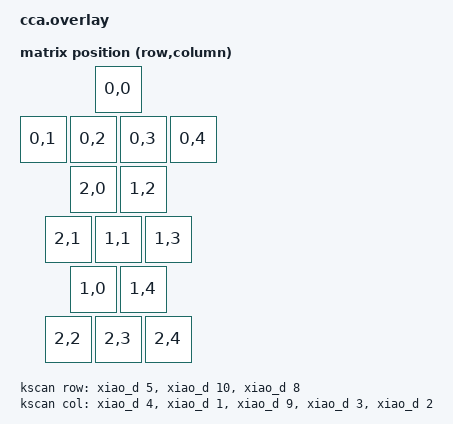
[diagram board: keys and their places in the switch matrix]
// This file was generated from a template. Edit it to match your keyboard.
// See https://zmk.dev/docs/development/hardware-integration/new-shield for more
// instructions.

#include <dt-bindings/zmk/matrix_transform.h>

#include "cca-layouts.dtsi"

/ {
    chosen {
        zmk,physical-layout = &default_layout;
    };

    kscan: kscan {
        compatible = "zmk,kscan-gpio-matrix";
        diode-direction = "col2row";
        wakeup-source;

        col-gpios
            = <&xiao_d 4 GPIO_ACTIVE_HIGH>
            , <&xiao_d 1 GPIO_ACTIVE_HIGH>
            , <&xiao_d 9 GPIO_ACTIVE_HIGH>
            , <&xiao_d 3 GPIO_ACTIVE_HIGH>
            , <&xiao_d 2 GPIO_ACTIVE_HIGH>
            ;

        row-gpios
            = <&xiao_d 5 (GPIO_ACTIVE_HIGH | GPIO_PULL_DOWN)>
            , <&xiao_d 10 (GPIO_ACTIVE_HIGH | GPIO_PULL_DOWN)>
            , <&xiao_d 8 (GPIO_ACTIVE_HIGH | GPIO_PULL_DOWN)>
            ;
    };

    default_transform: default_transform {
        compatible = "zmk,matrix-transform";
        columns = <5>;
        rows = <3>;

        map = <
            RC(0, 0)
            RC(0, 1) RC(0, 2) RC(0, 3) RC(0, 4)
                         RC(2, 0) RC(1, 2)
                     RC(2, 1) RC(1, 1) RC(1, 3)
                         RC(1, 0) RC(1, 4)
              RC(2, 2) RC(2, 3) RC(2, 4)
        >;
    };
};
